# CM23 register map
Registers are read-only, no defined reset value unless marked. A register's access mark holds for its fields unless they carry their own. Offsets are from the block's base; lines under a group give offsets from that group; [hi:lo] are bit positions; {n}, {i} and the like mark numbered series; 'fields as' and 'values as' point back to an identical list; <NAME> marks a mode.

## Memory map
0xE0040000 TPIU size 0x1000 — Trace Port Interface Unit

## TPIU — Trace Port Interface Unit
Base 0xE0040000
0x00 TPIU_SSPSR — TPIU Supported Parallel Port Sizes Register indicates the supported parallel trace port sizes
  [31:0] SWIDTH — Supported width. SWIDTH[m] indicates whether a parallel trace port width of (m+1) is supported
    0=Parallel trace port width (m+1) not supported; 1=Parallel trace port width (m+1) supported
0x04 TPIU_CSPSR rw — TPIU Current Parallel Port Sizes Register controls the width of the parallel trace port
  [31:0] CWIDTH — Current width. CWIDTH[m] represents a parallel trace port width of (m+1)
    0=Width (N+1) is not the current parallel trace port width; 1=Width (N+1) is the current parallel trace port width; 2=debugger must set only one bit is set to 1, and all others must be zero
0x10 TPIU_ACPR rw — TPIU Asynchronous Clock Prescaler Register defines a prescaler value for the baud rate of the Serial Wire Output (SWO)
  [15:0] SWOSCALER — SWO baud rate prescalar
0xF0 TPIU_SPPR rw — TPIU Selected Pin Protocol Register selects the protocol used for trace output
  [1:0] TXMODE — Transmit mode. Specifies the protocol for trace output from the TPIU
    0=Parallel trace port mode. This value is reserved if TPIU_TYPE.PTINVALID == 1; 1=Asynchronous SWO, using Manchester encoding
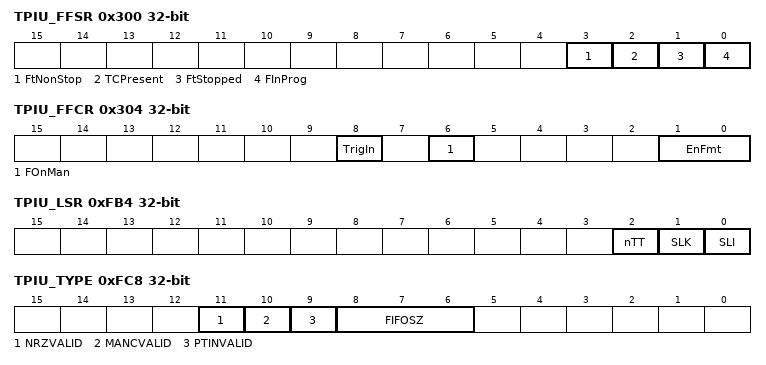
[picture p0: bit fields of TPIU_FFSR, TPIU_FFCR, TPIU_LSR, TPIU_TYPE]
0x300 TPIU_FFSR — TPIU Formatter and Flush Status Register shows the status and capabilities of the TPIU formatter
  [3] FtNonStop — Non-stop formatter. Indicates the formatter cannot be stopped
    0=Formatter can be stopped; 1=Formatter cannot be stopped
  [2] TCPresent — TRACECTL present. Indicates presence of the TRACECTL pin
    0=No TRACECTL pin is available
  [1] FtStopped — Formatter stopped. Indicates the formatter is stopped
    0=Formatter is enabled; 1=Formatter is stopped
  [0] FInProg — Flush in progress
0x304 TPIU_FFCR rw — TPIU Formatter and Flush Control Register controls the TPIU formatter
  [8] TrigIn — Trigger input asserted
  [6] FOnMan — Flush On Manual. Setting this bit to 1 generates a flush
  [1:0] EnFmt — Formatter control. Selects the output formatting mode
    0=Bypass. Disable formatting. Only supported when SWO mode is selected
0x308 TPIU_PSCR rw — TPIU Periodic Synchronization Control Register defines the reload value for the Periodic Synchronization Counter register
  [4:0] PSCount — Periodic Synchronization Count
    0=Synchronization disabled; 7=128 bytes; 8=256 bytes
0xFB0 TPIU_LAR wo — TPIU Software Lock Access Register provides CoreSight Software Lock control for the TPIU, see the CoreSight Architecture Specification for details
  [31:0] KEY — Lock Access control
0xFB4 TPIU_LSR — TPIU Software Lock Status Register provides CoreSight Software Lock status information for the TPIU, see the CoreSight Architecture Specification for details
  [2] nTT — Not thirty-two bit. See the CoreSight Architecture Specification
  [1] SLK — Software Lock status. See the CoreSight Architecture Specification
    0=Lock clear. Software writes are permitted to this component's registers; 1=Lock set
  [0] SLI — Software Lock implemented. See the CoreSight Architecture Specification
    0=Software Lock not implemented or debugger access; 1=Software Lock is implemented and software access
0xFC8 TPIU_TYPE — TPIU Device Identifier Register describes the TPIU to a debugger
  [11] NRZVALID — NRZ valid. Indicates support for SWO using UART/NRZ encoding
    0=Not supported; 1=Supported
  [10] MANCVALID — Manchester valid. Indicates support for SWO using Manchester encoding
    0=Not supported; 1=Supported
  [9] PTINVALID — Parallel Trace Interface invalid. Indicates support for parallel trace port operation
    0=Supported; 1=Not supported
  [8:6] FIFOSZ — FIFO depth. Indicates the minimum implemented size of the TPIU output FIFO for trace data
    0=IMPLEMENTATION DEFINED FIFO depth
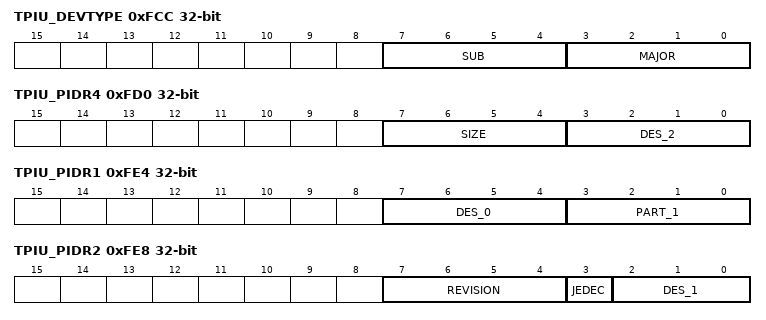
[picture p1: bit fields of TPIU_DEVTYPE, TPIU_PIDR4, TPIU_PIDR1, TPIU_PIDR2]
0xFCC TPIU_DEVTYPE — TPIU Device Type Register provides CoreSight discovery information for the TPIU
  [7:4] SUB — Subtype. Component subtype
    0=Other. Only permitted if the MAJOR field reads as 0x0; 1=Trace port. Only permitted if the MAJOR field reads as 0x1
  [3:0] MAJOR — Major type. Component major type
    0=Miscellaneous; 1=Trace sink
0xFD0 TPIU_PIDR4 — TPIU Peripheral Identification Register 4 provides CoreSight discovery information for the TPIU
  [7:4] SIZE — 4KB count. See the CoreSight Architecture Specification
  [3:0] DES_2 — JEP106 continuation code. See the CoreSight Architecture Specification
{0xFC0+4i} TPIU_PIDR{i} (i=5..7) — TPIU Peripheral Identification Register {i} provides CoreSight discovery information for the TPIU
0xFE0 TPIU_PIDR0 — TPIU Peripheral Identification Register 0 provides CoreSight discovery information for the TPIU
  [7:0] PART_0 — Part number bits [7:0]. See the CoreSight Architecture Specification
0xFE4 TPIU_PIDR1 — TPIU Peripheral Identification Register 1 provides CoreSight discovery information for the TPIU
  [7:4] DES_0 — JEP106 identification code bits [3:0]. See the CoreSight Architecture Specification
  [3:0] PART_1 — Part number bits [11:8]. See the CoreSight Architecture Specification
0xFE8 TPIU_PIDR2 — TPIU Peripheral Identification Register 2 provides CoreSight discovery information for the TPIU
  [7:4] REVISION — Component revision. See the CoreSight Architecture Specification
  [3] JEDEC — JEDEC assignee value is used. See the CoreSight Architecture Specification
  [2:0] DES_1 — JEP106 identification code bits [6:4]. See the CoreSight Architecture Specification
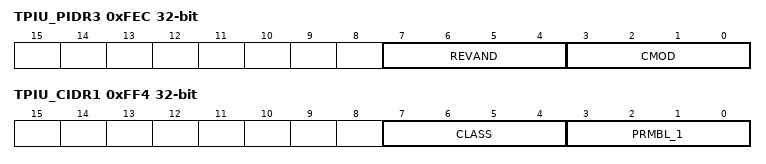
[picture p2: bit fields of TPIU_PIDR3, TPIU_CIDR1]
0xFEC TPIU_PIDR3 — TPIU Peripheral Identification Register 3 provides CoreSight discovery information for the TPIU
  [7:4] REVAND — RevAnd. See the CoreSight Architecture Specification
  [3:0] CMOD — Customer Modified. See the CoreSight Architecture Specification
0xFF0 TPIU_CIDR0 — TPIU Component Identification Register 0 provides CoreSight discovery information for the TPIU
  [7:0] PRMBL_0 — CoreSight component identification preamble
0xFF4 TPIU_CIDR1 — TPIU Component Identification Register 1 provides CoreSight discovery information for the TPIU
  [7:4] CLASS — CoreSight component class. See the CoreSight Architecture Specification
  [3:0] PRMBL_1 — CoreSight component identification preamble
0xFF8 TPIU_CIDR2 — TPIU Component Identification Register 2 provides CoreSight discovery information for the TPIU
  [7:0] PRMBL_2 — CoreSight component identification preamble
0xFFC TPIU_CIDR3 — TPIU Component Identification Register 3 provides CoreSight discovery information for the TPIU
  [7:0] PRMBL_3 — CoreSight component identification preamble
